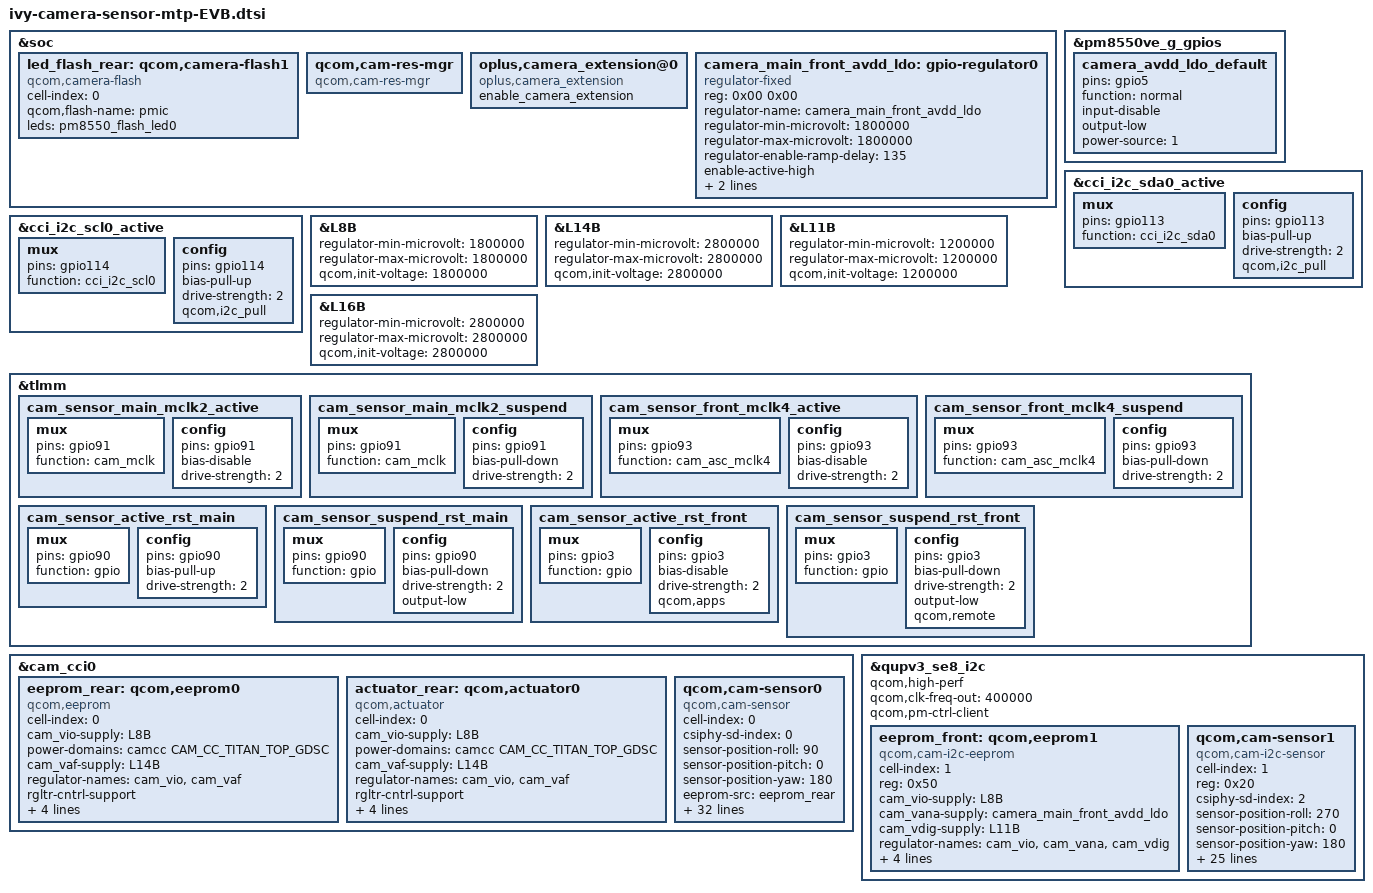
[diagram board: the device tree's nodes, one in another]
#include <dt-bindings/msm-camera.h>
#include "ftm_camera_settings.dtsi"

&soc {
	led_flash_rear: qcom,camera-flash1 {
		cell-index = <0>;
		compatible = "qcom,camera-flash";
		qcom,flash-name = "pmic";
		leds = <&pm8550_flash_led0>;
		status = "ok";
	};
	qcom,cam-res-mgr {
		compatible = "qcom,cam-res-mgr";
		status = "ok";
	};
	oplus,camera_extension@0 {
		compatible = "oplus,camera_extension";
		enable_camera_extension;
		status = "ok";
	};
	camera_main_front_avdd_ldo: gpio-regulator0 {
		compatible = "regulator-fixed";
		reg = <0x00 0x00>;
		regulator-name = "camera_main_front_avdd_ldo";
		regulator-min-microvolt = <1800000>;
		regulator-max-microvolt = <1800000>;
		regulator-enable-ramp-delay = <135>;
		enable-active-high;
		gpio = <&pm8550ve_g_gpios 5 0>;
		pinctrl-names = "default";
		pinctrl-0 = <&camera_avdd_ldo_default>;
	};
};

&pm8550ve_g_gpios {

	camera_avdd_ldo_default: camera_avdd_ldo_default {
		pins = "gpio5";
		function = "normal";
		input-disable;
		output-low;
		power-source = <1>;
	};
};

&cci_i2c_sda0_active{
	/* SDA0 */
	mux {
		pins = "gpio113";
		function = "cci_i2c_sda0";
	};

	config {
		pins = "gpio113";
		bias-pull-up; /* PULL UP*/
		drive-strength = <2>; /* 2 MA */
		qcom,i2c_pull;
	};
};

&cci_i2c_scl0_active{
	/* SCL0 */
	mux {
		pins = "gpio114";
		function = "cci_i2c_scl0";
	};

	config {
		pins = "gpio114";
		bias-pull-up; /* PULL UP*/
		drive-strength = <2>; /* 2 MA */
		qcom,i2c_pull;
	};
};

&L8B {
  regulator-min-microvolt = <1800000>;
  regulator-max-microvolt = <1800000>;
  qcom,init-voltage = <1800000>;
};

&L14B {
  regulator-min-microvolt = <2800000>;
  regulator-max-microvolt = <2800000>;
  qcom,init-voltage = <2800000>;
};

&L11B {
  regulator-min-microvolt = <1200000>;
  regulator-max-microvolt = <1200000>;
  qcom,init-voltage = <1200000>;
};

&L16B {
  regulator-min-microvolt = <2800000>;
  regulator-max-microvolt = <2800000>;
  qcom,init-voltage = <2800000>;
};


&tlmm {
	cam_sensor_main_mclk2_active: cam_sensor_main_mclk2_active {
		/* MCLK2 */
		mux {
			pins = "gpio91";
			function = "cam_mclk";
		};

		config {
			pins = "gpio91";
			bias-disable; /* No PULL */
			drive-strength = <2>; /* 2 MA */
		};
	};

	cam_sensor_main_mclk2_suspend: cam_sensor_main_mclk2_suspend {
		/* MCLK2 */
		mux {
			pins = "gpio91";
			function = "cam_mclk";
		};

		config {
			pins = "gpio91";
			bias-pull-down; /* PULL DOWN */
			drive-strength = <2>; /* 2 MA */
		};
	};


	cam_sensor_front_mclk4_active: cam_sensor_front_mclk4_active {
		/* MCLK4 */
		mux {
			pins = "gpio93";
			function = "cam_asc_mclk4";
		};

		config {
			pins = "gpio93";
			bias-disable; /* No PULL */
			drive-strength = <2>; /* 2 MA */
		};
	};

	cam_sensor_front_mclk4_suspend: cam_sensor_front_mclk4_suspend {
		/* MCLK4 */
		mux {
			pins = "gpio93";
			function = "cam_asc_mclk4";
		};

		config {
			pins = "gpio93";
			bias-pull-down; /* PULL DOWN */
			drive-strength = <2>; /* 2 MA */
		};
	};

	cam_sensor_active_rst_main: cam_sensor_active_rst_main {
		/* RST2 */
		mux {
			pins = "gpio90";
			function = "gpio";
		};

		config {
			pins = "gpio90";
			bias-pull-up; /* PULL UP*/
			drive-strength = <2>; /* 2 MA */
		};
	};

	cam_sensor_suspend_rst_main: cam_sensor_suspend_rst_main {
		/* RST2 */
		mux {
			pins = "gpio90";
			function = "gpio";
		};

		config {
			pins = "gpio90";
			bias-pull-down; /* PULL DOWN */
			drive-strength = <2>; /* 2 MA */
			output-low;
		};
	};


	cam_sensor_active_rst_front: cam_sensor_active_rst_front {
		/* RST4 */
		mux {
			pins = "gpio3";
			function = "gpio";
		};

		config {
			pins = "gpio3";
			bias-disable; /* No PULL */
			drive-strength = <2>; /* 2 MA */
			qcom,apps;
		};
	};

	cam_sensor_suspend_rst_front: cam_sensor_suspend_rst_front {
		/* RST4 */
		mux {
			pins = "gpio3";
			function = "gpio";
		};

		config {
			pins = "gpio3";
			bias-pull-down; /* PULL DOWN */
			drive-strength = <2>; /* 2 MA */
			output-low;
			qcom,remote;
		};
	};
};

&cam_cci0 {

	eeprom_rear: qcom,eeprom0 {
		cell-index = <0>;
		compatible = "qcom,eeprom";
		cam_vio-supply = <&L8B>;
		power-domains = <&camcc CAM_CC_TITAN_TOP_GDSC>;
		cam_vaf-supply = <&L14B>;
		regulator-names ="cam_vio","cam_vaf";
		rgltr-cntrl-support;
		rgltr-min-voltage = <1800000 2800000>;
		rgltr-max-voltage = <1800000 2800000>;
		rgltr-load-current = <300000 120000>;
		cci-master = <CCI_MASTER_0>;
		status = "ok";
	};

	actuator_rear: qcom,actuator0 {
		cell-index = <0>;
		compatible = "qcom,actuator";
		cam_vio-supply = <&L8B>;
		power-domains = <&camcc CAM_CC_TITAN_TOP_GDSC>;
		cam_vaf-supply = <&L14B>;
		regulator-names ="cam_vio","cam_vaf";
		rgltr-cntrl-support;
		rgltr-min-voltage = <1800000 2800000>;
		rgltr-max-voltage = <1800000 2800000>;
		rgltr-load-current = <300000 120000>;
		cci-master = <CCI_MASTER_0>;
		status = "ok";
	};

    //main camera
	qcom,cam-sensor0 {
		cell-index = <0>;
		compatible = "qcom,cam-sensor";
		csiphy-sd-index = <0>;
		sensor-position-roll = <90>;
		sensor-position-pitch = <0>;
		sensor-position-yaw = <180>;
		eeprom-src = <&eeprom_rear>;
		actuator-src = <&actuator_rear>;
		led-flash-src = <&led_flash_rear>;
		cam_vana-supply = <&camera_main_front_avdd_ldo>;
		cam_vdig-supply = <&L11B>;
		cam_vio-supply = <&L8B>;
		power-domains = <&camcc CAM_CC_TITAN_TOP_GDSC>;
		cam_vaf-supply = <&L14B>;
		regulator-names = "cam_vana", "cam_vdig","cam_vio","cam_vaf";
		rgltr-cntrl-support;
		rgltr-min-voltage = <1800000 1200000 1800000 2800000>;
		rgltr-max-voltage = <1800000 1200000 1800000 2800000>;
		rgltr-load-current = <600000 120000 300000 120000>;
		gpio-no-mux = <0>;
		pinctrl-names = "cam_default", "cam_suspend";
		pinctrl-0 = <&cam_sensor_main_mclk2_active
				&cam_sensor_active_rst_main>;
		pinctrl-1 = <&cam_sensor_main_mclk2_suspend
				&cam_sensor_suspend_rst_main>;
		gpios = <&tlmm 91 0>,
			<&tlmm 90 0>;
		gpio-reset = <1>;
		gpio-req-tbl-num = <0 1>;
		gpio-req-tbl-flags = <1 0>;
		gpio-req-tbl-label = "CAMIF_MCLK2",
				"CAM_RESET2";
		cci-master = <CCI_MASTER_0>;
		clocks = <&cambistmclkcc CAM_BIST_MCLK_CC_MCLK2_CLK>;
		clock-names = "cam_clk";
		clock-cntl-level = "nominal";
		clock-rates = <19200000>;
		//is-support-laser = <1>;
		//enable_qsc_write_in_advance = <1>;
		//qsc_reg_addr = <0x24C0>;
		//eeprom_slave_addr = <0xA0>;
		//qsc_data_size = <2304>;
		//write_qsc_addr = <0x5800>;
		ftm_setting_compatible = <'R' 0x3107 2 2 0xc658>; // expect camera_3107_c658
		status = "ok";
	};
};


&qupv3_se8_i2c {
	status = "ok";
	qcom,high-perf;
	qcom,clk-freq-out = <400000>;
	qcom,pm-ctrl-client;

	eeprom_front: qcom,eeprom1 {
		cell-index = <1>;
		reg = <0x50>;
		compatible = "qcom,cam-i2c-eeprom";
		cam_vio-supply = <&L8B>;
		cam_vana-supply = <&camera_main_front_avdd_ldo>;
		cam_vdig-supply = <&L11B>;
		regulator-names = "cam_vio", "cam_vana","cam_vdig";
		rgltr-cntrl-support;
		rgltr-min-voltage = <1800000 2800000 1200000>;
		rgltr-max-voltage = <1800000 2800000 1200000>;
		rgltr-load-current = <300000 600000 600000>;
		status = "ok";
	};

	qcom,cam-sensor1 {
		cell-index = <1>;
		reg = <0x20>;
		compatible = "qcom,cam-i2c-sensor";
		csiphy-sd-index = <2>;
		sensor-position-roll = <270>;
		sensor-position-pitch = <0>;
		sensor-position-yaw = <180>;
		eeprom-src = <&eeprom_front>;
		cam_vio-supply = <&L8B>;
		cam_vana-supply = <&camera_main_front_avdd_ldo>;
		cam_vdig-supply = <&L11B>;
		power-domains = <&camcc CAM_CC_TITAN_TOP_GDSC>;
		regulator-names = "cam_vio", "cam_vana","cam_vdig";
		rgltr-cntrl-support;
		rgltr-min-voltage = <1800000 1800000 1200000>;
		rgltr-max-voltage = <1800000 1800000 1200000>;
		rgltr-load-current = <300000 600000 600000>;
		gpio-no-mux = <0>;
		pinctrl-names = "cam_default", "cam_suspend";
		pinctrl-0 = <&cam_sensor_front_mclk4_active
				 &cam_sensor_active_rst_front>;
		pinctrl-1 = <&cam_sensor_front_mclk4_suspend
				 &cam_sensor_suspend_rst_front>;
		gpios = <&tlmm 93 0>,
			<&tlmm 3 0>;
		gpio-reset = <1>;
		gpio-req-tbl-num = <0 1>;
		gpio-req-tbl-flags = <1 0>;
		gpio-req-tbl-label = "CAMIF_MCLK4",
				"CAM_RESET4";
		clocks = <&cambistmclkcc CAM_BIST_MCLK_CC_MCLK4_CLK>;
		clock-names = "cam_clk";
		clock-cntl-level = "nominal";
		clock-rates = <19200000>;
		ftm_setting_compatible = <'R' 0x3107 2 2 0xd154>; // expect camera_3107_d154
		status = "ok";
	};
};
